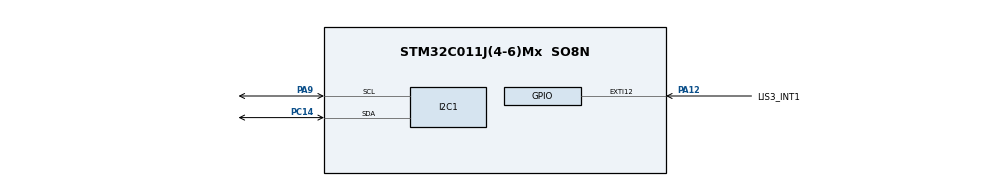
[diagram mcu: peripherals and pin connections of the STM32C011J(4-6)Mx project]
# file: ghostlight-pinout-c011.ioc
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ADC1.NbrOfConversionFlag=0
ADC1.SelectedChannel=ADC_CHANNEL_VREFINT
ADC1.master=1
Dma.ADC1.0.Direction=DMA_PERIPH_TO_MEMORY
Dma.ADC1.0.EventEnable=DISABLE
Dma.ADC1.0.Instance=DMA1_Channel1
Dma.ADC1.0.MemDataAlignment=DMA_MDATAALIGN_HALFWORD
Dma.ADC1.0.MemInc=DMA_MINC_ENABLE
Dma.ADC1.0.Mode=DMA_NORMAL
Dma.ADC1.0.PeriphDataAlignment=DMA_PDATAALIGN_HALFWORD
Dma.ADC1.0.PeriphInc=DMA_PINC_DISABLE
Dma.ADC1.0.Polarity=HAL_DMAMUX_REQ_GEN_RISING
Dma.ADC1.0.Priority=DMA_PRIORITY_LOW
Dma.ADC1.0.RequestNumber=1
Dma.ADC1.0.SignalID=NONE
Dma.ADC1.0.SyncEnable=DISABLE
Dma.ADC1.0.SyncPolarity=HAL_DMAMUX_SYNC_NO_EVENT
Dma.ADC1.0.SyncRequestNumber=1
Dma.ADC1.0.SyncSignalID=NONE
Dma.I2C1_RX.1.Direction=DMA_PERIPH_TO_MEMORY
Dma.I2C1_RX.1.EventEnable=DISABLE
Dma.I2C1_RX.1.Instance=DMA1_Channel2
Dma.I2C1_RX.1.MemDataAlignment=DMA_MDATAALIGN_BYTE
Dma.I2C1_RX.1.MemInc=DMA_MINC_ENABLE
Dma.I2C1_RX.1.Mode=DMA_NORMAL
Dma.I2C1_RX.1.PeriphDataAlignment=DMA_PDATAALIGN_BYTE
Dma.I2C1_RX.1.PeriphInc=DMA_PINC_DISABLE
Dma.I2C1_RX.1.Polarity=HAL_DMAMUX_REQ_GEN_RISING
Dma.I2C1_RX.1.Priority=DMA_PRIORITY_LOW
Dma.I2C1_RX.1.RequestNumber=1
Dma.I2C1_RX.1.SignalID=NONE
Dma.I2C1_RX.1.SyncEnable=DISABLE
Dma.I2C1_RX.1.SyncPolarity=HAL_DMAMUX_SYNC_NO_EVENT
Dma.I2C1_RX.1.SyncRequestNumber=1
Dma.I2C1_RX.1.SyncSignalID=NONE
Dma.I2C1_TX.2.Direction=DMA_MEMORY_TO_PERIPH
Dma.I2C1_TX.2.EventEnable=DISABLE
Dma.I2C1_TX.2.Instance=DMA1_Channel3
Dma.I2C1_TX.2.MemDataAlignment=DMA_MDATAALIGN_BYTE
Dma.I2C1_TX.2.MemInc=DMA_MINC_ENABLE
Dma.I2C1_TX.2.Mode=DMA_NORMAL
Dma.I2C1_TX.2.PeriphDataAlignment=DMA_PDATAALIGN_BYTE
Dma.I2C1_TX.2.PeriphInc=DMA_PINC_DISABLE
Dma.I2C1_TX.2.Polarity=HAL_DMAMUX_REQ_GEN_RISING
Dma.I2C1_TX.2.Priority=DMA_PRIORITY_LOW
Dma.I2C1_TX.2.RequestNumber=1
Dma.I2C1_TX.2.SignalID=NONE
Dma.I2C1_TX.2.SyncEnable=DISABLE
Dma.I2C1_TX.2.SyncPolarity=HAL_DMAMUX_SYNC_NO_EVENT
Dma.I2C1_TX.2.SyncRequestNumber=1
Dma.I2C1_TX.2.SyncSignalID=NONE
Dma.Request0=ADC1
Dma.Request1=I2C1_RX
Dma.Request2=I2C1_TX
I2C1.Timing=0x00402D41
Mcu.Family=STM32C0
Mcu.Name=STM32C011J(4-6)Mx
Mcu.Package=SO8N
NVIC.DMA1_Channel1_IRQn=true\:0\:0\:false\:false\:true\:false\:true\:true
NVIC.DMA1_Channel2_3_IRQn=true\:0\:0\:false\:false\:true\:false\:true\:true
NVIC.EXTI4_15_IRQn=true\:0\:0\:false\:false\:true\:true\:true\:true
NVIC.TIM14_IRQn=true\:0\:0\:false\:false\:true\:true\:true\:true
PA12\ [PA10].GPIO_Label=LIS3_INT1
PA12\ [PA10].Signal=GPXTI12
PA13.Mode=Serial_Wire
PA13.Signal=DEBUG_SWDIO
PA14-BOOT0.Mode=Serial_Wire
PA14-BOOT0.Signal=DEBUG_SWCLK
PA8__PA11\ [PA9].StandardMode=true
PA9\ [PA11].Mode=I2C
PA9\ [PA11].Signal=I2C1_SCL
PC14-OSCX_IN\ (PC14).Mode=I2C
PC14-OSCX_IN\ (PC14).Signal=I2C1_SDA
PC14-OSCX_IN\ (PC14)__PB7.StandardMode=true
PC15-OSCX_OUT\ (PC15)__PA14-BOOT0__PB6.StandardMode=true
PF2-NRST__PA0__PA1__PA2.StandardMode=true
ProjectManager.HeapSize=0x200
ProjectManager.StackSize=0x400
ProjectManager.TargetToolchain=STM32CubeIDE
RCC.ADCFreq_Value=12000000
RCC.AHBFreq_Value=12000000
RCC.CortexFreq_Value=12000000
RCC.EXTERNAL_CLOCK_VALUE=12288000
RCC.HCLKFreq_Value=12000000
RCC.HSE_VALUE=8000000
RCC.HSI_VALUE=48000000
RCC.LSE_VALUE=32768
RCC.SYSCLKFreq_VALUE=12000000
VP_ADC1_Vref_Input.Mode=IN-Vrefint
VP_SYS_VS_PINREMAP.Mode=PINREMAP
VP_TIM14_VS_ClockSourceINT.Mode=Enable_Timer
board=custom

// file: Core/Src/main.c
/* USER CODE BEGIN Header */
/**
 ******************************************************************************
 * @file           : main.c
 * @brief          : Main program body
 ******************************************************************************
 * @attention
 *
 * Copyright (c) 2026 STMicroelectronics.
 * All rights reserved.
 *
 * This software is licensed under terms that can be found in the LICENSE file
 * in the root directory of this software component.
 * If no LICENSE file comes with this software, it is provided AS-IS.
 *
 ******************************************************************************
 */
/* USER CODE END Header */
#include "main.h"
#include "adc.h"
#include "dma.h"
#include "i2c.h"
#include "tim.h"
#include "gpio.h"

/* USER CODE BEGIN Includes */
#include "LP5817.h"
#include "LIS3DH.h"
/* USER CODE END Includes */

/* USER CODE BEGIN PV */
volatile int mode = 0;
volatile int measure = 1;
volatile int change_mod = 0;
/* USER CODE END PV */

void SystemClock_Config(void);

/* USER CODE BEGIN 0 */
void handleI2CErr(uint8_t error_code) {
	//HAL_GPIO_WritePin(LIVE_GPIO_Port, LIVE_Pin, RESET);
	// Check if any error occurred (Bit 0 is our 'Error Present' marker)
	if (error_code) {
		while (1) {
		}
	}
}

#define MAX_BRIGHT 100
#define SCALE(val) ((val * MAX_BRIGHT) / 255)

/**
 * @brief set color based on the hue(0-329)
 *
 * @param hue, number between 0 and 365, which chooses specific HUE
 */
void SetRainbowColor(uint16_t hue) {
	uint8_t r = 0, g = 0, b = 0;
	uint8_t region = hue / 60;
	uint8_t remainder = (hue % 60) * 255 / 60;

	uint8_t p = 0; // Matching 0% brightness base
	uint8_t q = 255 - remainder;
	uint8_t t = remainder;

	// Scale down from 255 to your maximum target brightness (e.g., max 150 to not blind you)

	switch (region) {
	case 0:
		r = 255;
		g = t;
		b = p;
		break;
	case 1:
		r = q;
		g = 255;
		b = p;
		break;
	case 2:
		r = p;
		g = 255;
		b = t;
		break;
	case 3:
		r = p;
		g = q;
		b = 255;
		break;
	case 4:
		r = t;
		g = p;
		b = 255;
		break;
	default:
		r = 255;
		g = p;
		b = q;
		break;
	}

	// Call your driver with the scaled relaxing colors
	LP5817_setColor(SCALE(r), SCALE(g), SCALE(b));
}

/**
 * @brief rutine, which cycles thru hues (0-359) in 30 ms intervals
 */
void rainbowRutine() {
	static uint16_t hue = 0;
	SetRainbowColor(hue);

	hue++;
	if (hue >= 360) {
		hue = 0;
	}

	HAL_Delay(30);
}

/**
 * @brief rutine, which sets colour based on accelerometer output
 */
void displayLISOutputRutine() {
	static int16_t accel_x = 0;
	static int16_t accel_y = 0;
	static int16_t accel_z = 0;
	//Update colour based on accelerometer output
	LIS3DH_getAxes(&accel_x, &accel_y, &accel_z);
	// 2. Convert to absolute values (so upside-down or backwards movement still creates light)
	// We divide by 4 to map ~1000 (1G of gravity) down to ~250 (perfect for an 8-bit LED channel)
	int16_t r_val = (accel_x >= 0 ? accel_x : (-accel_x)) / 64;
	int16_t g_val = (accel_y >= 0 ? accel_y : (-accel_y)) / 64;
	int16_t b_val = (accel_z >= 0 ? accel_z : (-accel_z)) / 64;

	// 3. Constrain the values between 0 and 255 just to protect against high-acceleration spikes
	if (r_val > 255)
		r_val = 255;
	if (g_val > 255)
		g_val = 255;
	if (b_val > 255)
		b_val = 255;
	if (r_val < b_val && r_val < g_val) {
		r_val = 0;
	} else if (b_val < g_val) {
		b_val = 0;
	} else {
		g_val = 0;
	}
	LP5817_setColor(SCALE((uint8_t )r_val), SCALE((uint8_t )g_val),
			SCALE((uint8_t )b_val));
	// Adjust this delay to speed up or slow down the transition.
	// 30ms gives a beautifully smooth, tranquil fade.
	HAL_Delay(30);
}

void updateMode() {
	if (measure) {
		int16_t x = 0, y = 0, z = 0;
		LIS3DH_getAxes(&x, &y, &z);

		if (change_mod) {
			//check z
			if (z < -10000) {
				mode++;
				mode %= 10;
			}
			change_mod = 0;
		} else {
			int32_t x_scaled = x / 64;
			int32_t y_scaled = y / 64;
			if ((x_scaled * x_scaled) + (y_scaled * y_scaled) > 50000) {
				change_mod = 1;
			}
		}
		measure = 0;
	}
}
/* USER CODE END 0 */

int main(void)
{

  /* MCU Configuration--------------------------------------------------------*/

  /* Reset of all peripherals, Initializes the Flash interface and the Systick. */
  HAL_Init();

  /* Configure the system clock */
  SystemClock_Config();

  /* Initialize all configured peripherals */
  MX_GPIO_Init();
  MX_DMA_Init();
  MX_I2C1_Init();
  MX_ADC1_Init();
  MX_TIM14_Init();
  /* USER CODE BEGIN 2 */

	uint8_t i2c_err = LP5817_init();
	HAL_Delay(1);
	handleI2CErr(i2c_err);

	LP5817_setColor(255, 0, 0);

	i2c_err = LIS3DH_init();
	HAL_Delay(1);
	handleI2CErr(i2c_err);

	HAL_Delay(500);

  /* USER CODE END 2 */

  /* Infinite loop */
	while (1) {

    /* USER CODE BEGIN 3 */
		uint8_t clear_buffer = 0;
		LIS3DH_read_reg(0x31, &clear_buffer, 1);

		switch (mode) {
		case 0:
			rainbowRutine();
			break;
		case 1:
			//red
			LP5817_setColor(SCALE(255), 0, 0);
			__WFI();
			break;
		case 2:
			//green
			LP5817_setColor(0, SCALE(255), 0);
			__WFI();
			break;
		case 3:
			//blue
			LP5817_setColor(0, 0, SCALE(255));
			__WFI();
			break;
		case 4:
			//magenta
			LP5817_setColor(SCALE(255), 0, SCALE(255));
			__WFI();
			break;
		case 5:
			//yellow
			LP5817_setColor(SCALE(255), SCALE(255), 0);
			__WFI();
			break;
		case 6:
			//cyan?
			LP5817_setColor(0, SCALE(255), SCALE(255));
			__WFI();
			break;
		case 7:
			//white
			LP5817_setColor(255, 255, 255);
			__WFI();
			break;
		case 8:
			//off
			LP5817_setColor(0, 0, 0);
			__WFI();
			break;
		case 9:
			displayLISOutputRutine();
		};

	}
  /* USER CODE END 3 */
}

void SystemClock_Config(void)
{
  RCC_OscInitTypeDef RCC_OscInitStruct = {0};
  RCC_ClkInitTypeDef RCC_ClkInitStruct = {0};

  __HAL_FLASH_SET_LATENCY(FLASH_LATENCY_0);

  /** Initializes the RCC Oscillators according to the specified parameters
  * in the RCC_OscInitTypeDef structure.
  */
  RCC_OscInitStruct.OscillatorType = RCC_OSCILLATORTYPE_HSI;
  RCC_OscInitStruct.HSIState = RCC_HSI_ON;
  RCC_OscInitStruct.HSIDiv = RCC_HSI_DIV4;
  RCC_OscInitStruct.HSICalibrationValue = RCC_HSICALIBRATION_DEFAULT;
  if (HAL_RCC_OscConfig(&RCC_OscInitStruct) != HAL_OK)
  {
    Error_Handler();
  }

  /** Initializes the CPU, AHB and APB buses clocks
  */
  RCC_ClkInitStruct.ClockType = RCC_CLOCKTYPE_HCLK|RCC_CLOCKTYPE_SYSCLK
                              |RCC_CLOCKTYPE_PCLK1;
  RCC_ClkInitStruct.SYSCLKSource = RCC_SYSCLKSOURCE_HSI;
  RCC_ClkInitStruct.SYSCLKDivider = RCC_SYSCLK_DIV1;
  RCC_ClkInitStruct.AHBCLKDivider = RCC_HCLK_DIV1;
  RCC_ClkInitStruct.APB1CLKDivider = RCC_APB1_DIV1;

  if (HAL_RCC_ClockConfig(&RCC_ClkInitStruct, FLASH_LATENCY_0) != HAL_OK)
  {
    Error_Handler();
  }
}

/* USER CODE BEGIN 4 */
void HAL_GPIO_EXTI_Rising_Callback(uint16_t GPIO_Pin) {
	if (GPIO_Pin == LIS3_INT1_Pin) {
		measure = 1;
	}
}
/* USER CODE END 4 */

void Error_Handler(void)
{
	__disable_irq();
	while (1) {
	}
}
